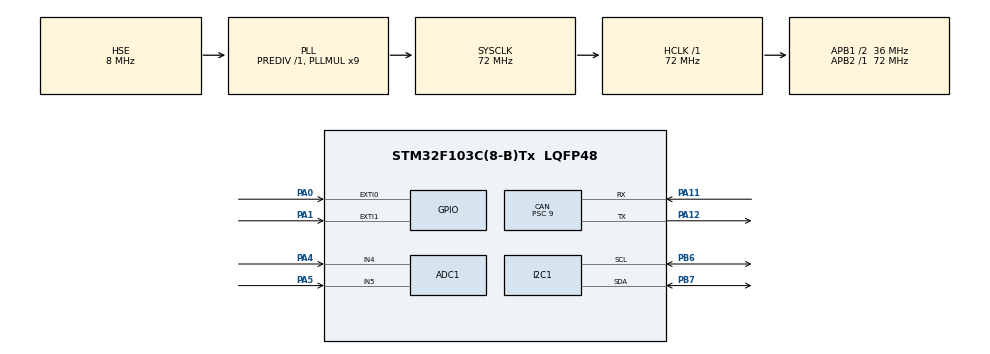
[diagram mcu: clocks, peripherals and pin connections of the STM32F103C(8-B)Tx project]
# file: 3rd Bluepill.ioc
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ADC1.Channel-0\#ChannelRegularConversion=ADC_CHANNEL_4
ADC1.NbrOfConversionFlag=1
ADC1.Rank-0\#ChannelRegularConversion=1
ADC1.SamplingTime-0\#ChannelRegularConversion=ADC_SAMPLETIME_1CYCLE_5
ADC1.master=1
CAN.ABOM=ENABLE
CAN.BS1=CAN_BS1_6TQ
CAN.BS2=CAN_BS2_1TQ
CAN.CalculateBaudRate=500000
CAN.CalculateTimeBit=2000
CAN.CalculateTimeQuantum=250.0
CAN.Prescaler=9
Mcu.Family=STM32F1
Mcu.Name=STM32F103C(8-B)Tx
Mcu.Package=LQFP48
NVIC.EXTI0_IRQn=true\:0\:0\:false\:false\:true\:true\:true\:true
NVIC.EXTI1_IRQn=true\:0\:0\:false\:false\:true\:true\:true\:true
NVIC.PriorityGroup=NVIC_PRIORITYGROUP_4
PA0-WKUP.GPIO_ModeDefaultEXTI=GPIO_MODE_IT_FALLING
PA0-WKUP.GPIO_PuPd=GPIO_PULLUP
PA0-WKUP.Signal=GPXTI0
PA1.GPIO_ModeDefaultEXTI=GPIO_MODE_IT_FALLING
PA1.GPIO_PuPd=GPIO_PULLUP
PA1.Signal=GPXTI1
PA11.Mode=CAN_Activate
PA11.Signal=CAN_RX
PA12.Mode=CAN_Activate
PA12.Signal=CAN_TX
PA13.Mode=Serial_Wire
PA13.Signal=SYS_JTMS-SWDIO
PA14.Mode=Serial_Wire
PA14.Signal=SYS_JTCK-SWCLK
PA4.Signal=ADCx_IN4
PA5.Signal=ADCx_IN5
PB6.Mode=I2C
PB6.Signal=I2C1_SCL
PB7.Mode=I2C
PB7.Signal=I2C1_SDA
PD0-OSC_IN.Mode=HSE-External-Oscillator
PD0-OSC_IN.Signal=RCC_OSC_IN
PD1-OSC_OUT.Mode=HSE-External-Oscillator
PD1-OSC_OUT.Signal=RCC_OSC_OUT
ProjectManager.HeapSize=0x200
ProjectManager.StackSize=0x400
ProjectManager.TargetToolchain=STM32CubeIDE
RCC.ADCPresc=RCC_ADCPCLK2_DIV6
RCC.AHBFreq_Value=72000000
RCC.APB1CLKDivider=RCC_HCLK_DIV2
RCC.APB1Freq_Value=36000000
RCC.APB1TimFreq_Value=72000000
RCC.APB2Freq_Value=72000000
RCC.APB2TimFreq_Value=72000000
RCC.HCLKFreq_Value=72000000
RCC.PLLMUL=RCC_PLL_MUL9
RCC.PLLSourceVirtual=RCC_PLLSOURCE_HSE
RCC.SYSCLKFreq_VALUE=72000000
RCC.SYSCLKSource=RCC_SYSCLKSOURCE_PLLCLK
RCC.USBFreq_Value=72000000
SH.ADCx_IN4.0=ADC1_IN4,IN4
SH.ADCx_IN5.0=ADC1_IN5,IN5
board=custom

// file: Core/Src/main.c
/* USER CODE BEGIN Header */
/**
  ******************************************************************************
  * @file           : main.c
  * @brief          : CAN telemetry node
  ******************************************************************************
  * @attention
  *
  * Copyright (c) 2026 STMicroelectronics.
  * All rights reserved.
  *
  * This software is licensed under terms that can be found in the LICENSE file
  * in the root directory of this software component.
  * If no LICENSE file comes with this software, it is provided AS-IS.
  *
  ******************************************************************************
  */
/* USER CODE END Header */
#include "main.h"

/* USER CODE BEGIN Includes */
#include "can_node_v2.h"
/* USER CODE END Includes */

ADC_HandleTypeDef hadc1;

CAN_HandleTypeDef hcan;

I2C_HandleTypeDef hi2c1;

void SystemClock_Config(void);
static void MX_GPIO_Init(void);
static void MX_CAN_Init(void);
static void MX_ADC1_Init(void);
static void MX_I2C1_Init(void);

int main(void)
{

  /* MCU Configuration--------------------------------------------------------*/

  /* Reset of all peripherals, Initializes the Flash interface and the Systick. */
  HAL_Init();

  /* Configure the system clock */
  SystemClock_Config();

  /* Initialize all configured peripherals */
  MX_GPIO_Init();
  MX_CAN_Init();
  MX_ADC1_Init();
  MX_I2C1_Init();
  /* USER CODE BEGIN 2 */
  can_node_v2_init(&hcan);
  /* USER CODE END 2 */

  /* Infinite loop */
  while (1)
  {

    /* USER CODE BEGIN 3 */
    can_node_v2_task();
  }
  /* USER CODE END 3 */
}

void SystemClock_Config(void)
{
  RCC_OscInitTypeDef RCC_OscInitStruct = {0};
  RCC_ClkInitTypeDef RCC_ClkInitStruct = {0};
  RCC_PeriphCLKInitTypeDef PeriphClkInit = {0};

  /** Initializes the RCC Oscillators according to the specified parameters
  * in the RCC_OscInitTypeDef structure.
  */
  RCC_OscInitStruct.OscillatorType = RCC_OSCILLATORTYPE_HSE;
  RCC_OscInitStruct.HSEState = RCC_HSE_ON;
  RCC_OscInitStruct.HSEPredivValue = RCC_HSE_PREDIV_DIV1;
  RCC_OscInitStruct.HSIState = RCC_HSI_ON;
  RCC_OscInitStruct.PLL.PLLState = RCC_PLL_ON;
  RCC_OscInitStruct.PLL.PLLSource = RCC_PLLSOURCE_HSE;
  RCC_OscInitStruct.PLL.PLLMUL = RCC_PLL_MUL9;
  if (HAL_RCC_OscConfig(&RCC_OscInitStruct) != HAL_OK)
  {
    Error_Handler();
  }

  /** Initializes the CPU, AHB and APB buses clocks
  */
  RCC_ClkInitStruct.ClockType = RCC_CLOCKTYPE_HCLK|RCC_CLOCKTYPE_SYSCLK
                              |RCC_CLOCKTYPE_PCLK1|RCC_CLOCKTYPE_PCLK2;
  RCC_ClkInitStruct.SYSCLKSource = RCC_SYSCLKSOURCE_PLLCLK;
  RCC_ClkInitStruct.AHBCLKDivider = RCC_SYSCLK_DIV1;
  RCC_ClkInitStruct.APB1CLKDivider = RCC_HCLK_DIV2;
  RCC_ClkInitStruct.APB2CLKDivider = RCC_HCLK_DIV1;

  if (HAL_RCC_ClockConfig(&RCC_ClkInitStruct, FLASH_LATENCY_2) != HAL_OK)
  {
    Error_Handler();
  }
  PeriphClkInit.PeriphClockSelection = RCC_PERIPHCLK_ADC;
  PeriphClkInit.AdcClockSelection = RCC_ADCPCLK2_DIV6;
  if (HAL_RCCEx_PeriphCLKConfig(&PeriphClkInit) != HAL_OK)
  {
    Error_Handler();
  }
}

static void MX_ADC1_Init(void)
{

  ADC_ChannelConfTypeDef sConfig = {0};

  /** Common config
  */
  hadc1.Instance = ADC1;
  hadc1.Init.ScanConvMode = ADC_SCAN_DISABLE;
  hadc1.Init.ContinuousConvMode = DISABLE;
  hadc1.Init.DiscontinuousConvMode = DISABLE;
  hadc1.Init.ExternalTrigConv = ADC_SOFTWARE_START;
  hadc1.Init.DataAlign = ADC_DATAALIGN_RIGHT;
  hadc1.Init.NbrOfConversion = 1;
  if (HAL_ADC_Init(&hadc1) != HAL_OK)
  {
    Error_Handler();
  }

  /** Configure Regular Channel
  */
  sConfig.Channel = ADC_CHANNEL_4;
  sConfig.Rank = ADC_REGULAR_RANK_1;
  sConfig.SamplingTime = ADC_SAMPLETIME_1CYCLE_5;
  if (HAL_ADC_ConfigChannel(&hadc1, &sConfig) != HAL_OK)
  {
    Error_Handler();
  }

}

static void MX_CAN_Init(void)
{

  hcan.Instance = CAN1;
  hcan.Init.Prescaler = 9;
  hcan.Init.Mode = CAN_MODE_NORMAL;
  hcan.Init.SyncJumpWidth = CAN_SJW_1TQ;
  hcan.Init.TimeSeg1 = CAN_BS1_6TQ;
  hcan.Init.TimeSeg2 = CAN_BS2_1TQ;
  hcan.Init.TimeTriggeredMode = DISABLE;
  hcan.Init.AutoBusOff = ENABLE;
  hcan.Init.AutoWakeUp = DISABLE;
  hcan.Init.AutoRetransmission = DISABLE;
  hcan.Init.ReceiveFifoLocked = DISABLE;
  hcan.Init.TransmitFifoPriority = DISABLE;
  if (HAL_CAN_Init(&hcan) != HAL_OK)
  {
    Error_Handler();
  }

}

static void MX_I2C1_Init(void)
{

  hi2c1.Instance = I2C1;
  hi2c1.Init.ClockSpeed = 100000;
  hi2c1.Init.DutyCycle = I2C_DUTYCYCLE_2;
  hi2c1.Init.OwnAddress1 = 0;
  hi2c1.Init.AddressingMode = I2C_ADDRESSINGMODE_7BIT;
  hi2c1.Init.DualAddressMode = I2C_DUALADDRESS_DISABLE;
  hi2c1.Init.OwnAddress2 = 0;
  hi2c1.Init.GeneralCallMode = I2C_GENERALCALL_DISABLE;
  hi2c1.Init.NoStretchMode = I2C_NOSTRETCH_DISABLE;
  if (HAL_I2C_Init(&hi2c1) != HAL_OK)
  {
    Error_Handler();
  }

}

static void MX_GPIO_Init(void)
{
  GPIO_InitTypeDef GPIO_InitStruct = {0};

  /* GPIO Ports Clock Enable */
  __HAL_RCC_GPIOD_CLK_ENABLE();
  __HAL_RCC_GPIOA_CLK_ENABLE();
  __HAL_RCC_GPIOB_CLK_ENABLE();

  /*Configure GPIO pins : PA0 PA1 */
  GPIO_InitStruct.Pin = GPIO_PIN_0|GPIO_PIN_1;
  GPIO_InitStruct.Mode = GPIO_MODE_IT_FALLING;
  GPIO_InitStruct.Pull = GPIO_PULLUP;
  HAL_GPIO_Init(GPIOA, &GPIO_InitStruct);

  /* EXTI interrupt init*/
  HAL_NVIC_SetPriority(EXTI0_IRQn, 0, 0);
  HAL_NVIC_EnableIRQ(EXTI0_IRQn);

  HAL_NVIC_SetPriority(EXTI1_IRQn, 0, 0);
  HAL_NVIC_EnableIRQ(EXTI1_IRQn);

}

void Error_Handler(void)
{
  __disable_irq();
  while (1)
  {
  }
}
